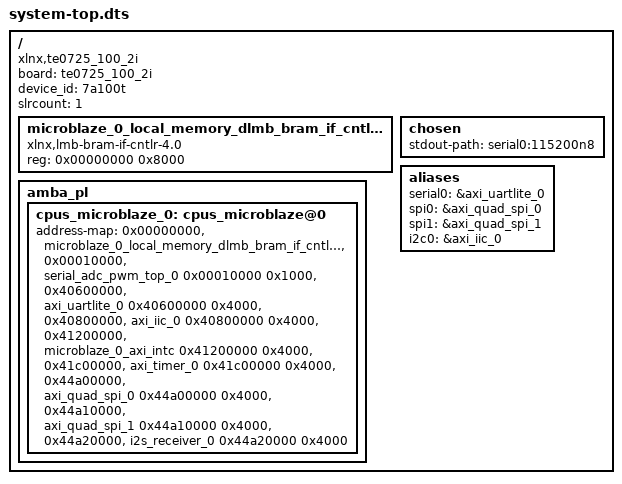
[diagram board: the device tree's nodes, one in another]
/dts-v1/;
#include "pl.dtsi"
/ {
	board = "te0725_100_2i";
	compatible = "xlnx,te0725_100_2i";
	device_id = "7a100t";
	#address-cells = <1>;
	#size-cells = <1>;
	slrcount = <1>;
	microblaze_0_local_memory_dlmb_bram_if_cntlr_memory: memory@0 {
		compatible = "xlnx,lmb-bram-if-cntlr-4.0";
		device_type = "memory";
		reg = <0x00000000 0x8000>;
	};
	chosen {
		stdout-path = "serial0:115200n8";
	};
	aliases {
		serial0 = &axi_uartlite_0;
		spi0 = &axi_quad_spi_0;
		spi1 = &axi_quad_spi_1;
		i2c0 = &axi_iic_0;
	};
	amba_pl: amba_pl {
		cpus_microblaze_0: cpus_microblaze@0 {
			address-map = <0x00000000 &microblaze_0_local_memory_dlmb_bram_if_cntlr_memory 0x00000000 0x8000>, 
			      <0x00010000 &serial_adc_pwm_top_0 0x00010000 0x1000>, 
			      <0x40600000 &axi_uartlite_0 0x40600000 0x4000>, 
			      <0x40800000 &axi_iic_0 0x40800000 0x4000>, 
			      <0x41200000 &microblaze_0_axi_intc 0x41200000 0x4000>, 
			      <0x41c00000 &axi_timer_0 0x41c00000 0x4000>, 
			      <0x44a00000 &axi_quad_spi_0 0x44a00000 0x4000>, 
			      <0x44a10000 &axi_quad_spi_1 0x44a10000 0x4000>, 
			      <0x44a20000 &i2s_receiver_0 0x44a20000 0x4000>;
			#ranges-address-cells = <0x1>;
			#ranges-size-cells = <0x1>;
		};
	};
};
